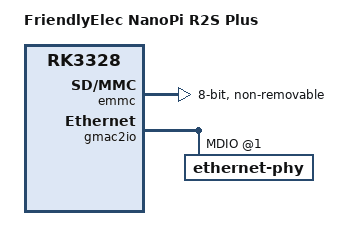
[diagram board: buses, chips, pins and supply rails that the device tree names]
// SPDX-License-Identifier: (GPL-2.0+ OR MIT)
/*
 * (C) Copyright 2018 FriendlyElec Computer Tech. Co., Ltd.
 * (http://www.friendlyarm.com)
 *
 * (C) Copyright 2016 Rockchip Electronics Co., Ltd
 */

/dts-v1/;

#include "rk3328-nanopi-r2s.dts"

/ {
	compatible = "friendlyarm,nanopi-r2s-plus", "rockchip,rk3328";
	model = "FriendlyElec NanoPi R2S Plus";

	aliases {
		mmc1 = &emmc;
	};
};

&emmc {
	bus-width = <8>;
	cap-mmc-highspeed;
	disable-wp;
	mmc-hs200-1_8v;
	non-removable;
	pinctrl-names = "default";
	pinctrl-0 = <&emmc_clk &emmc_cmd &emmc_bus8>;
	status = "okay";
};

&gmac2io {
	snps,reset-delays-us = <0 20000 100000>;
	tx_delay = <0x1a>;
	rx_delay = <0x14>;

	mdio {
		ethernet-phy@1 {
			reset-assert-us = <20000>;
			reset-dassert-us = <100000>;
			max-speed = <1000>;
		};
	};
};
